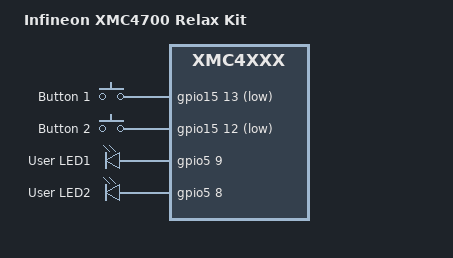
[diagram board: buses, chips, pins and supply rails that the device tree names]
/*
 * SPDX-License-Identifier: Apache-2.0
 *
 * Copyright (c) 2020 Linumiz
 * Author: Parthiban Nallathambi <parthiban@linumiz.com>
 *
 */

/dts-v1/;

#include <infineon/xmc4700/xmc4700_f144x2048.dtsi>

/ {
	model = "Infineon XMC4700 Relax Kit";
	compatible = "infineon,xm4700-relax-kit", "infineon,xmc4700",
                        "infineon,xmc4xxx";

	chosen {
		zephyr,sram = &sram0;
		zephyr,dtcm = &dtcm;
		zephyr,ccm = &ccm;
		zephyr,flash = &flash0;
	};

	buttons {
		compatible = "gpio-keys";
		user_button_1: button1 {
			label = "Button 1";
			gpios = <&gpio15 13 GPIO_ACTIVE_LOW>;
		};
		user_button_2: button2 {
			label = "Button 2";
			gpios = <&gpio15 12 GPIO_ACTIVE_LOW>;
		};
	};

	leds {
		compatible = "gpio-leds";
		red_led_1: led_1 {
			gpios = <&gpio5 9 GPIO_ACTIVE_HIGH>;
			label = "User LED1";
		};

		red_led_2: led_2 {
			gpios = <&gpio5 8 GPIO_ACTIVE_HIGH>;
			label = "User LED2";
		};
	};

	aliases {
		led0 = &red_led_2;
		sw0 = &user_button_1; 
	};
	
};

&cpu0 {
	clock-frequency = <144000000>;
};
